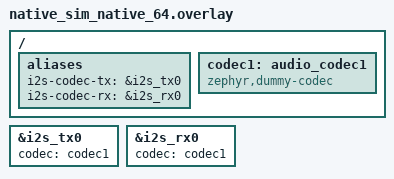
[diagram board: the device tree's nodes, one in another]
/*
 * Copyright 2026 NXP
 *
 * SPDX-License-Identifier: Apache-2.0
 */

/ {
	aliases {
		i2s-codec-tx = &i2s_tx0;
		i2s-codec-rx = &i2s_rx0;
	};

	codec1: audio_codec1 {
		compatible = "zephyr,dummy-codec";
		status = "okay";
	};
};

&i2s_tx0 {
	codec = <&codec1>;
	status = "okay";
};

&i2s_rx0 {
	codec = <&codec1>;
	status = "okay";
};
